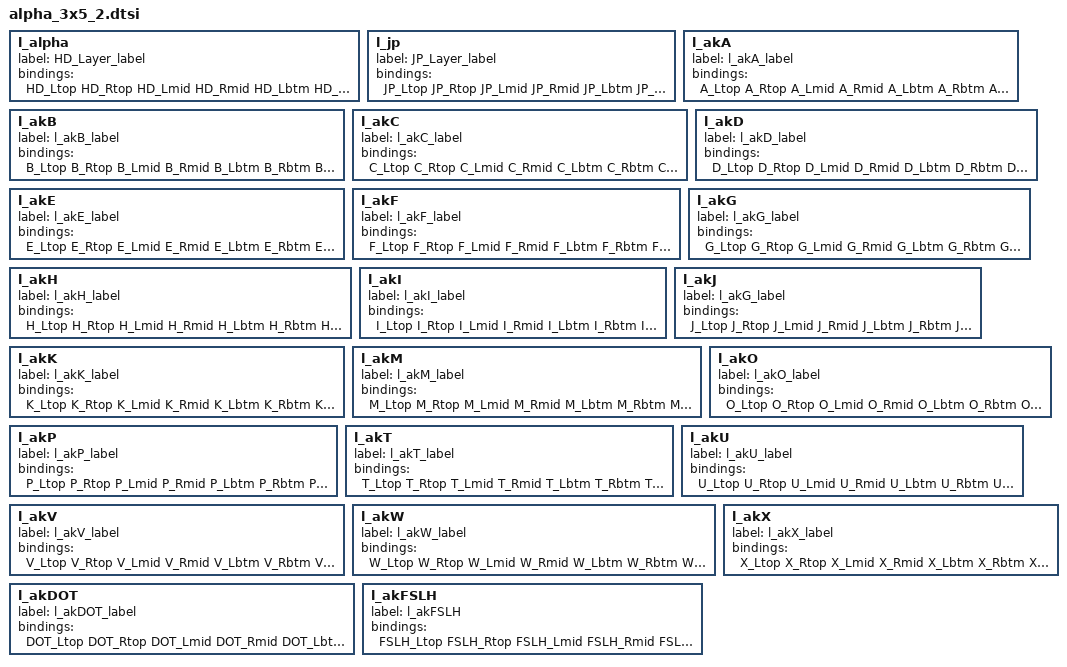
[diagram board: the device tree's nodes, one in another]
/*  Base (alpha) Layers & associated adaptive key layers on a 34 key board
    The values here are all defined in the corresponding HD-##.h file
*/

            l_alpha {
                label = HD_Layer_label;
                bindings = <
                                HD_Ltop         HD_Rtop
                                HD_Lmid         HD_Rmid
                                HD_Lbtm         HD_Rbtm
                                HD_Lthm         HD_Rthm
                        >;
                    };
            l_jp {
                label = JP_Layer_label; // Japanese "mode" (L, C, X not used in Japanese, so repurpose to ん, Z, -)
                bindings = <
                                JP_Ltop         JP_Rtop
                                JP_Lmid         JP_Rmid
                                JP_Lbtm         JP_Rbtm
                                JP_Lthm         JP_Rthm
                >;
            };
            l_akA {
                label = l_akA_label;
                bindings = <
                                A_Ltop         A_Rtop
                                A_Lmid         A_Rmid
                                A_Lbtm         A_Rbtm
                                A_Lthm         A_Rthm
                >;
            };
            l_akB {
                label = l_akB_label;
                bindings = <
                                B_Ltop         B_Rtop
                                B_Lmid         B_Rmid
                                B_Lbtm         B_Rbtm
                                B_Lthm         B_Rthm
                >;
            };
            l_akC {
                label = l_akC_label;
                bindings = <
                                C_Ltop         C_Rtop
                                C_Lmid         C_Rmid
                                C_Lbtm         C_Rbtm
                                C_Lthm         C_Rthm
                >;
            };
            l_akD {
                label = l_akD_label;
                bindings = <
                                D_Ltop         D_Rtop
                                D_Lmid         D_Rmid
                                D_Lbtm         D_Rbtm
                                D_Lthm         D_Rthm
                >;
            };
            l_akE {
                label = l_akE_label;
                bindings = <
                                E_Ltop         E_Rtop
                                E_Lmid         E_Rmid
                                E_Lbtm         E_Rbtm
                                E_Lthm         E_Rthm
                >;
            };
            l_akF {
                label = l_akF_label;
                bindings = <
                                F_Ltop         F_Rtop
                                F_Lmid         F_Rmid
                                F_Lbtm         F_Rbtm
                                F_Lthm         F_Rthm
                >;
            };
            l_akG {
                label = l_akG_label;
                bindings = <
                                G_Ltop         G_Rtop
                                G_Lmid         G_Rmid
                                G_Lbtm         G_Rbtm
                                G_Lthm         G_Rthm
                >;
            };
            l_akH {
                label = l_akH_label;
                bindings = <
                                H_Ltop         H_Rtop
                                H_Lmid         H_Rmid
                                H_Lbtm         H_Rbtm
                                H_Lthm         H_Rthm
                >;
            };
            l_akI {
                label = l_akI_label;
                bindings = <
                                I_Ltop         I_Rtop
                                I_Lmid         I_Rmid
                                I_Lbtm         I_Rbtm
                                I_Lthm         I_Rthm
                >;
            };
            l_akJ {
                label = l_akG_label;
                bindings = <
                                J_Ltop         J_Rtop
                                J_Lmid         J_Rmid
                                J_Lbtm         J_Rbtm
                                J_Lthm         J_Rthm
                >;
            };
            l_akK {
                label = l_akK_label;
                bindings = <
                                K_Ltop         K_Rtop
                                K_Lmid         K_Rmid
                                K_Lbtm         K_Rbtm
                                K_Lthm         K_Rthm
                >;
            };
            l_akM {
                label = l_akM_label;
                bindings = <
                                M_Ltop         M_Rtop
                                M_Lmid         M_Rmid
                                M_Lbtm         M_Rbtm
                                M_Lthm         M_Rthm
                >;
            };
            l_akO {
                label = l_akO_label;
                bindings = <
                                O_Ltop         O_Rtop
                                O_Lmid         O_Rmid
                                O_Lbtm         O_Rbtm
                                O_Lthm         O_Rthm
                >;
            };
            l_akP {
                label = l_akP_label;
                bindings = <
                                P_Ltop         P_Rtop
                                P_Lmid         P_Rmid
                                P_Lbtm         P_Rbtm
                                P_Lthm         P_Rthm
                >;
            };
            l_akT {
                label = l_akT_label;
                bindings = <
                                T_Ltop         T_Rtop
                                T_Lmid         T_Rmid
                                T_Lbtm         T_Rbtm
                                T_Lthm         T_Rthm
                >;
            };
            l_akU {
                label = l_akU_label;
                bindings = <
                                U_Ltop         U_Rtop
                                U_Lmid         U_Rmid
                                U_Lbtm         U_Rbtm
                                U_Lthm         U_Rthm
                >;
            };
            l_akV {
                label = l_akV_label;
                bindings = <
                                V_Ltop         V_Rtop
                                V_Lmid         V_Rmid
                                V_Lbtm         V_Rbtm
                                V_Lthm         V_Rthm
                >;
            };
            l_akW {
                label = l_akW_label;
                bindings = <
                                W_Ltop         W_Rtop
                                W_Lmid         W_Rmid
                                W_Lbtm         W_Rbtm
                                W_Lthm         W_Rthm
                >;
            };
            l_akX {
                label = l_akX_label;
                bindings = <
                                X_Ltop         X_Rtop
                                X_Lmid         X_Rmid
                                X_Lbtm         X_Rbtm
                                X_Lthm         X_Rthm
                >;
            };
            l_akDOT {
                label = l_akDOT_label;
                bindings = <
                                DOT_Ltop       DOT_Rtop
                                DOT_Lmid       DOT_Rmid
                                DOT_Lbtm       DOT_Rbtm
                                DOT_Lthm       DOT_Rthm
                >;
            };
            l_akFSLH {
                label = "l_akFSLH";
                bindings = <
                                FSLH_Ltop      FSLH_Rtop
                                FSLH_Lmid      FSLH_Rmid
                                FSLH_Lbtm      FSLH_Rbtm
                                FSLH_Lthm      FSLH_Rthm
                >;
            };
